# Z20K14xM register map
Vendor: Zhixin Semiconductor; Series: Z20K14xM; File version: 0.1.0
CPU: CM4 r0p1, little endian, no MPU, FPU, 4 interrupt priority bits
Registers are 32-bit, read-write, reset 0x0 unless marked. A register's access mark holds for its fields unless they carry their own. Offsets are from the block's base; [hi:lo] are bit positions.

## TMU
Base 0x40063000
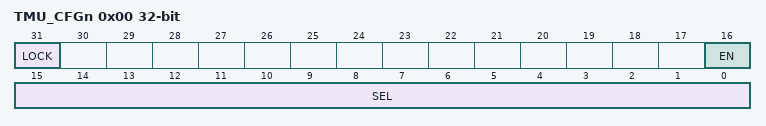
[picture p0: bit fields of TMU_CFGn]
0x00 TMU_CFGn — Trig Mux Unit Configuration(TMU_CFG)
  [31] LOCK — Write register lock
  [16] EN — Mux Output Enable
  [15:0] SEL — Mux Input Select

## CMP
Base 0x40073000
0x00 CMP_VERID ro — Version ID register(CMP_VERID)
  [31:0] VERID — CMP version number
0x04 CMP_PARAM ro reset 0x2 — Parameter register
  [3:0] DAC_RES — DAC resolution
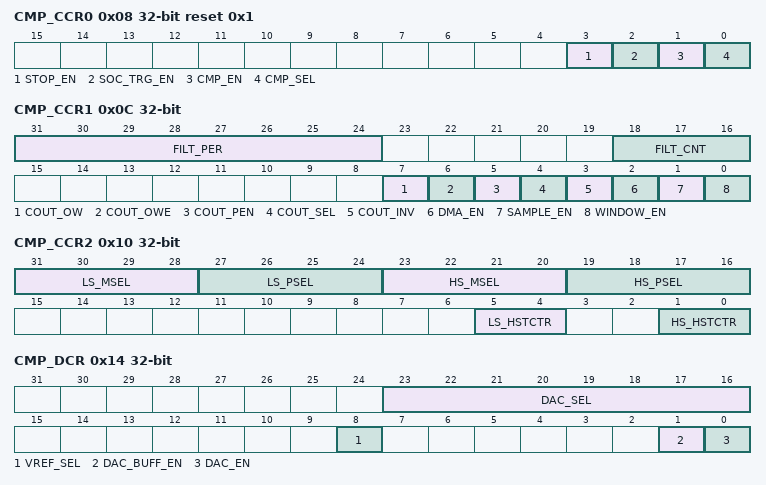
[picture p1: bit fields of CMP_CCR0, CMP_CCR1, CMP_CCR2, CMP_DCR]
0x08 CMP_CCR0 reset 0x1 — Comparator control register0(CMP_CCR0)
  [3] STOP_EN — stop enable bit
  [2] SOC_TRG_EN — SOC trigger enable
  [1] CMP_EN — comparator enable
  [0] CMP_SEL — Low speed/high speed comparator select
0x0C CMP_CCR1 — Comparator control register1(CMP_CCR1)
  [31:24] FILT_PER — Filter sample period
  [18:16] FILT_CNT — Filer sample count
  [7] COUT_OW — COUT level when window is closed
  [6] COUT_OWE — COUT level when window is closed, enbale bit
  [5] COUT_PEN — Cout output to pad
  [4] COUT_SEL — Cout select
  [3] COUT_INV — Comparator invert
  [2] DMA_EN — DMA enbale
  [1] SAMPLE_EN — sample mode enable
  [0] WINDOW_EN — Window mode enable
0x10 CMP_CCR2 — Comparator control register2(CMP_CCR2)
  [31:28] LS_MSEL — low speed CMP NMUX select
  [27:24] LS_PSEL — low speed CMP PMUX select
  [23:20] HS_MSEL — High speed CMP NMUX select
  [19:16] HS_PSEL — High speed CMP PMUX select
  [5:4] LS_HSTCTR — low-speed cmp hyst select
  [1:0] HS_HSTCTR — High-speed cmp hyst select
0x14 CMP_DCR — DAC control register(CMP_DCR)
  [23:16] DAC_SEL — DAC output Voltage select
  [8] VREF_SEL — DAC reference select
  [1] DAC_BUFF_EN — Reserved
  [0] DAC_EN — DAC enable
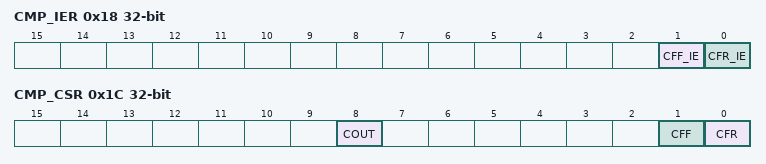
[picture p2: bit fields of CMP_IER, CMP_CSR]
0x18 CMP_IER — Interrupt enable register(CMP_IER)
  [1] CFF_IE — Comparator flag falling interrupt enable
  [0] CFR_IE — Comparator flag raising interrupt enable
0x1C CMP_CSR — Comparator status register(CMP_CSR)
  [8] COUT — Analog comparator output
  [1] CFF — Comparator output falling edge
  [0] CFR — Comparator output raising edge

## RTC
Base 0x40079000
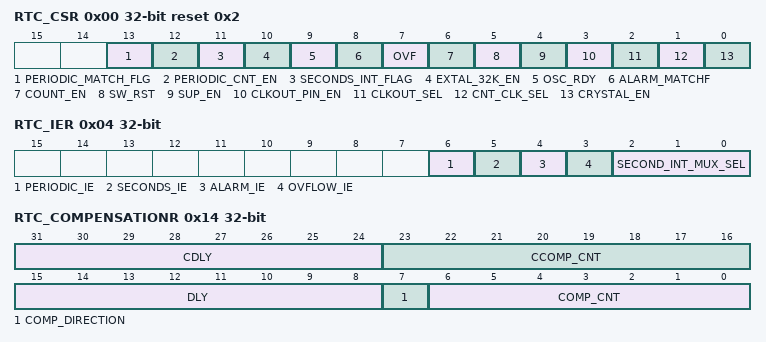
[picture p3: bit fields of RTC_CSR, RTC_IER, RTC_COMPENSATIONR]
0x00 RTC_CSR reset 0x2 — RTC control and status register (RTC_CSR)
  [13] PERIODIC_MATCH_FLG — RTC perriodic counter match flag
  [12] PERIODIC_CNT_EN — RTC periodic counter enable
  [11] SECONDS_INT_FLAG — seconds interrupt flag
  [10] EXTAL_32K_EN — extal 32K enable bit
  [9] OSC_RDY — OSC32K ready
  [8] ALARM_MATCHF — RTC alarm match flag
  [7] OVF — RTC overflow flag
  [6] COUNT_EN — RTC timer counter enable
  [5] SW_RST — software reset
  [4] SUP_EN — supervisor mode enable
  [3] CLKOUT_PIN_EN — RTC output clock to pin output enable
  [2] CLKOUT_SEL — RTC output clock to pin output enable
  [1] CNT_CLK_SEL — RTC one second counter clock source select bit
  [0] CRYSTAL_EN — internal 32K crystal enable
0x04 RTC_IER — RTC interrupt enable register(RTC_IER)
  [6] PERIODIC_IE — RTC periodic timer interrupt enable
  [5] SECONDS_IE — seconds interrut enable
  [4] ALARM_IE — RTC timer alarm match interrupt enable
  [3] OVFLOW_IE — RTC overflow interrupt enable
  [2:0] SECOND_INT_MUX_SEL — seconds interrupt mux selection
0x08 RTC_ALARM_CNTR — RTC alarm counter register(RTC_ALARM_CNTR)
  [31:0] ALARM_CNT — alarm counter value
0x0C RTC_ONE_SECOND_CNTR — RTC one second counter register
  [15:0] ONE_SECOND_CNT — one seconds counter value
0x10 RTC_MATCH_CNTR reset 0xFFFFFFFF — RTC match counter register(RTC_MATCH_CNTR)
  [31:0] MATCH_CNT — Reserved
0x14 RTC_COMPENSATIONR — RTC compensation register(RTC_COMPENSATIONR)
  [31:24] CDLY — current compensation delay value
  [23:16] CCOMP_CNT — current compensation counter value
  [15:8] DLY — compensation delay value
  [7] COMP_DIRECTION — frequency compensation direction
  [6:0] COMP_CNT — compensation counter value.
0x18 RTC_LOCKR reset 0x80000000 — RTC lock register (RTC_LOCKR)
  [31] LOCK — lock bit
0x1C RTC_VERID reset 0x4 — RTC version ID(RTC_VERID)
  [31:0] VERID — version ID
0x20 RTC_PERIODIC_TMR_CNT — RTC periodic timer counter
  [31:0] PERIODIC_TMR_CNT — periodic timer counter
0x24 RTC_PERIODIC_TMR_MATCH_CNT reset 0xFFFFFFFF — RTC periodic timer match counter
  [31:0] PERIODIC_MATCH_CNT — periodic timer match counter
